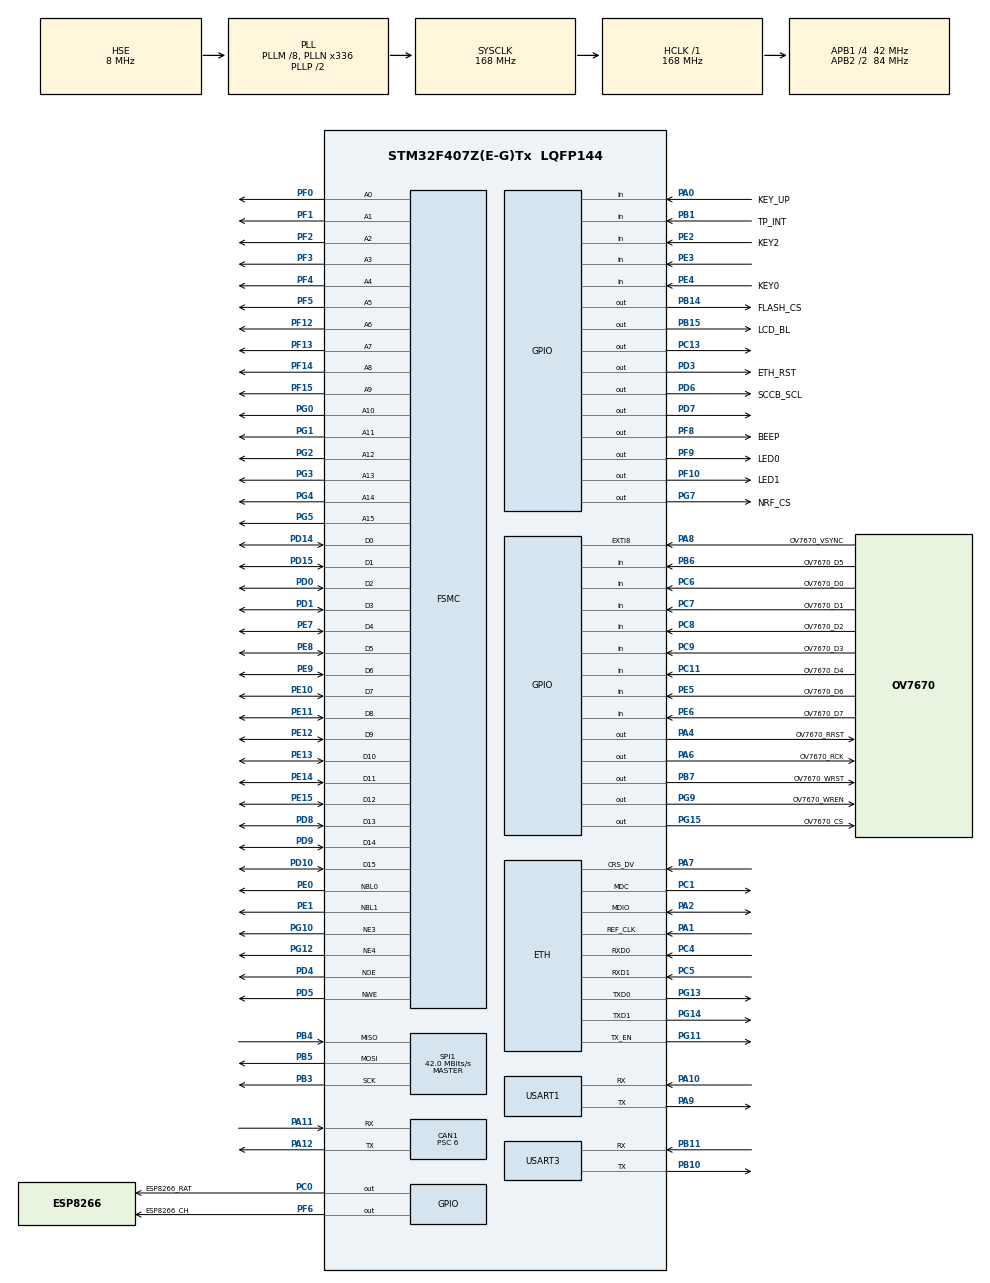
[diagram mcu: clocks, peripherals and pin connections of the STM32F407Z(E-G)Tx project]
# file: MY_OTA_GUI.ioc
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CAN1.BS1=CAN_BS1_11TQ
CAN1.BS2=CAN_BS2_2TQ
CAN1.CalculateBaudRate=500000
CAN1.CalculateTimeBit=2000
CAN1.CalculateTimeQuantum=142.85714285714286
CAN1.Prescaler=6
ETH.MediaInterface=HAL_ETH_RMII_MODE
FREERTOS.Tasks01=defaultTask,24,128,StartDefaultTask,Default,NULL,Dynamic,NULL,NULL
FREERTOS.configENABLE_FPU=1
FREERTOS.configTOTAL_HEAP_SIZE=65536
FSMC.AddressSetupTime3=0
FSMC.AddressSetupTime4=0
FSMC.BusTurnAroundDuration3=0
FSMC.BusTurnAroundDuration4=5
FSMC.DataSetupTime3=24
FSMC.DataSetupTime4=30
FSMC.WriteOperation3=FSMC_WRITE_OPERATION_ENABLE
FSMC.WriteOperation4=FSMC_WRITE_OPERATION_ENABLE
Mcu.Family=STM32F4
Mcu.Name=STM32F407Z(E-G)Tx
Mcu.Package=LQFP144
NVIC.EXTI9_5_IRQn=true\:5\:0\:false\:false\:true\:true\:true\:true\:true
NVIC.PriorityGroup=NVIC_PRIORITYGROUP_4
NVIC.TIM3_IRQn=true\:15\:0\:false\:false\:true\:false\:false\:true\:true
NVIC.TimeBase=TIM3_IRQn
NVIC.TimeBaseIP=TIM3
NVIC.USART1_IRQn=true\:5\:0\:false\:false\:true\:true\:true\:true\:true
PA0-WKUP.GPIO_Label=KEY_UP
PA0-WKUP.GPIO_PuPd=GPIO_PULLDOWN
PA0-WKUP.Signal=GPIO_Input
PA1.Mode=RMII
PA1.Signal=ETH_REF_CLK
PA10.Mode=Asynchronous
PA10.Signal=USART1_RX
PA11.Mode=CAN_Activate
PA11.Signal=CAN1_RX
PA12.Mode=CAN_Activate
PA12.Signal=CAN1_TX
PA13.Mode=Serial_Wire
PA13.Signal=SYS_JTMS-SWDIO
PA14.Mode=Serial_Wire
PA14.Signal=SYS_JTCK-SWCLK
PA2.Mode=RMII
PA2.Signal=ETH_MDIO
PA4.GPIO_Label=OV7670_RRST
PA4.Signal=GPIO_Output
PA6.GPIO_Label=OV7670_RCK
PA6.Signal=GPIO_Output
PA7.Mode=RMII
PA7.Signal=ETH_CRS_DV
PA8.GPIO_Label=OV7670_VSYNC
PA8.GPIO_ModeDefaultEXTI=GPIO_MODE_IT_FALLING
PA8.Signal=GPXTI8
PA9.Mode=Asynchronous
PA9.Signal=USART1_TX
PB1.GPIO_Label=TP_INT
PB1.GPIO_PuPd=GPIO_PULLUP
PB1.Signal=GPIO_Input
PB10.Mode=Asynchronous
PB10.Signal=USART3_TX
PB11.Mode=Asynchronous
PB11.Signal=USART3_RX
PB14.GPIO_Label=FLASH_CS
PB14.GPIO_PuPd=GPIO_PULLUP
PB14.PinState=GPIO_PIN_SET
PB14.Signal=GPIO_Output
PB15.GPIO_Label=LCD_BL
PB15.GPIO_PuPd=GPIO_PULLDOWN
PB15.Signal=GPIO_Output
PB3.GPIO_Speed=GPIO_SPEED_FREQ_MEDIUM
PB3.Mode=Full_Duplex_Master
PB3.Signal=SPI1_SCK
PB4.GPIO_Speed=GPIO_SPEED_FREQ_MEDIUM
PB4.Mode=Full_Duplex_Master
PB4.Signal=SPI1_MISO
PB5.GPIO_Speed=GPIO_SPEED_FREQ_MEDIUM
PB5.Mode=Full_Duplex_Master
PB5.Signal=SPI1_MOSI
PB6.GPIO_Label=OV7670_D5
PB6.GPIO_PuPd=GPIO_PULLDOWN
PB6.Signal=GPIO_Input
PB7.GPIO_Label=OV7670_WRST
PB7.Signal=GPIO_Output
PC0.GPIO_Label=ESP8266_RAT
PC0.PinState=GPIO_PIN_SET
PC0.Signal=GPIO_Output
PC1.Mode=RMII
PC1.Signal=ETH_MDC
PC11.GPIO_Label=OV7670_D4
PC11.GPIO_PuPd=GPIO_PULLDOWN
PC11.Signal=GPIO_Input
PC13-ANTI_TAMP.Signal=GPIO_Output
PC4.Mode=RMII
PC4.Signal=ETH_RXD0
PC5.Mode=RMII
PC5.Signal=ETH_RXD1
PC6.GPIO_Label=OV7670_D0
PC6.GPIO_PuPd=GPIO_PULLDOWN
PC6.Signal=GPIO_Input
PC7.GPIO_Label=OV7670_D1
PC7.GPIO_PuPd=GPIO_PULLDOWN
PC7.Signal=GPIO_Input
PC8.GPIO_Label=OV7670_D2
PC8.GPIO_PuPd=GPIO_PULLDOWN
PC8.Signal=GPIO_Input
PC9.GPIO_Label=OV7670_D3
PC9.GPIO_PuPd=GPIO_PULLDOWN
PC9.Signal=GPIO_Input
PD0.GPIO_Speed_High_Default=GPIO_SPEED_FREQ_MEDIUM
PD0.Signal=FSMC_D2_DA2
PD1.GPIO_Speed_High_Default=GPIO_SPEED_FREQ_MEDIUM
PD1.Signal=FSMC_D3_DA3
PD10.GPIO_Speed_High_Default=GPIO_SPEED_FREQ_MEDIUM
PD10.Signal=FSMC_D15_DA15
PD14.GPIO_Speed_High_Default=GPIO_SPEED_FREQ_MEDIUM
PD14.Signal=FSMC_D0_DA0
PD15.GPIO_Speed_High_Default=GPIO_SPEED_FREQ_MEDIUM
PD15.Signal=FSMC_D1_DA1
PD3.GPIO_Label=ETH_RST
PD3.GPIO_PuPd=GPIO_PULLUP
PD3.PinState=GPIO_PIN_SET
PD3.Signal=GPIO_Output
PD4.GPIO_Speed_High_Default=GPIO_SPEED_FREQ_MEDIUM
PD4.Signal=FSMC_NOE
PD5.GPIO_Speed_High_Default=GPIO_SPEED_FREQ_MEDIUM
PD5.Signal=FSMC_NWE
PD6.GPIO_Label=SCCB_SCL
PD6.GPIO_ModeDefaultOutputPP=GPIO_MODE_OUTPUT_OD
PD6.GPIO_PuPd=GPIO_PULLUP
PD6.PinState=GPIO_PIN_SET
PD6.Signal=GPIO_Output
PD7.GPIO_ModeDefaultOutputPP=GPIO_MODE_OUTPUT_OD
PD7.GPIO_PuPd=GPIO_PULLUP
PD7.Signal=GPIO_Output
PD8.GPIO_Speed_High_Default=GPIO_SPEED_FREQ_MEDIUM
PD8.Signal=FSMC_D13_DA13
PD9.GPIO_Speed_High_Default=GPIO_SPEED_FREQ_MEDIUM
PD9.Signal=FSMC_D14_DA14
PE0.GPIO_Speed_High_Default=GPIO_SPEED_FREQ_MEDIUM
PE0.Signal=FSMC_NBL0
PE1.GPIO_Speed_High_Default=GPIO_SPEED_FREQ_MEDIUM
PE1.Signal=FSMC_NBL1
PE10.GPIO_Speed_High_Default=GPIO_SPEED_FREQ_MEDIUM
PE10.Signal=FSMC_D7_DA7
PE11.GPIO_Speed_High_Default=GPIO_SPEED_FREQ_MEDIUM
PE11.Signal=FSMC_D8_DA8
PE12.GPIO_Speed_High_Default=GPIO_SPEED_FREQ_MEDIUM
PE12.Signal=FSMC_D9_DA9
PE13.GPIO_Speed_High_Default=GPIO_SPEED_FREQ_MEDIUM
PE13.Signal=FSMC_D10_DA10
PE14.GPIO_Speed_High_Default=GPIO_SPEED_FREQ_MEDIUM
PE14.Signal=FSMC_D11_DA11
PE15.GPIO_Speed_High_Default=GPIO_SPEED_FREQ_MEDIUM
PE15.Signal=FSMC_D12_DA12
PE2.GPIO_Label=KEY2
PE2.GPIO_PuPd=GPIO_PULLUP
PE2.Signal=GPIO_Input
PE3.Signal=GPIO_Input
PE4.GPIO_Label=KEY0
PE4.GPIO_PuPd=GPIO_PULLUP
PE4.Signal=GPIO_Input
PE5.GPIO_Label=OV7670_D6
PE5.GPIO_PuPd=GPIO_PULLDOWN
PE5.Signal=GPIO_Input
PE6.GPIO_Label=OV7670_D7
PE6.GPIO_PuPd=GPIO_PULLDOWN
PE6.Signal=GPIO_Input
PE7.GPIO_Speed_High_Default=GPIO_SPEED_FREQ_MEDIUM
PE7.Signal=FSMC_D4_DA4
PE8.GPIO_Speed_High_Default=GPIO_SPEED_FREQ_MEDIUM
PE8.Signal=FSMC_D5_DA5
PE9.GPIO_Speed_High_Default=GPIO_SPEED_FREQ_MEDIUM
PE9.Signal=FSMC_D6_DA6
PF0.GPIO_Speed_High_Default=GPIO_SPEED_FREQ_MEDIUM
PF0.Signal=FSMC_A0
PF1.GPIO_Speed_High_Default=GPIO_SPEED_FREQ_MEDIUM
PF1.Signal=FSMC_A1
PF10.GPIO_Label=LED1
PF10.GPIO_PuPd=GPIO_PULLUP
PF10.PinState=GPIO_PIN_SET
PF10.Signal=GPIO_Output
PF12.GPIO_Speed_High_Default=GPIO_SPEED_FREQ_MEDIUM
PF12.Signal=FSMC_A6
PF13.GPIO_Speed_High_Default=GPIO_SPEED_FREQ_MEDIUM
PF13.Signal=FSMC_A7
PF14.GPIO_Speed_High_Default=GPIO_SPEED_FREQ_MEDIUM
PF14.Signal=FSMC_A8
PF15.GPIO_Speed_High_Default=GPIO_SPEED_FREQ_MEDIUM
PF15.Signal=FSMC_A9
PF2.GPIO_Speed_High_Default=GPIO_SPEED_FREQ_MEDIUM
PF2.Signal=FSMC_A2
PF3.GPIO_Speed_High_Default=GPIO_SPEED_FREQ_MEDIUM
PF3.Signal=FSMC_A3
PF4.GPIO_Speed_High_Default=GPIO_SPEED_FREQ_MEDIUM
PF4.Signal=FSMC_A4
PF5.GPIO_Speed_High_Default=GPIO_SPEED_FREQ_MEDIUM
PF5.Signal=FSMC_A5
PF6.GPIO_Label=ESP8266_CH
PF6.PinState=GPIO_PIN_SET
PF6.Signal=GPIO_Output
PF8.GPIO_Label=BEEP
PF8.GPIO_PuPd=GPIO_PULLDOWN
PF8.PinState=GPIO_PIN_RESET
PF8.Signal=GPIO_Output
PF9.GPIO_Label=LED0
PF9.GPIO_PuPd=GPIO_PULLUP
PF9.PinState=GPIO_PIN_SET
PF9.Signal=GPIO_Output
PG0.GPIO_Speed_High_Default=GPIO_SPEED_FREQ_MEDIUM
PG0.Signal=FSMC_A10
PG1.GPIO_Speed_High_Default=GPIO_SPEED_FREQ_MEDIUM
PG1.Signal=FSMC_A11
PG10.GPIO_Speed_High_Default=GPIO_SPEED_FREQ_MEDIUM
PG10.Mode=NorPsramChipSelect3_3
PG10.Signal=FSMC_NE3
PG11.Mode=RMII
PG11.Signal=ETH_TX_EN
PG12.GPIO_Speed_High_Default=GPIO_SPEED_FREQ_MEDIUM
PG12.Mode=NorPsramChipSelect4_4
PG12.Signal=FSMC_NE4
PG13.Mode=RMII
PG13.Signal=ETH_TXD0
PG14.Mode=RMII
PG14.Signal=ETH_TXD1
PG15.GPIO_Label=OV7670_CS
PG15.PinState=GPIO_PIN_SET
PG15.Signal=GPIO_Output
PG2.GPIO_Speed_High_Default=GPIO_SPEED_FREQ_MEDIUM
PG2.Signal=FSMC_A12
PG3.GPIO_Speed_High_Default=GPIO_SPEED_FREQ_MEDIUM
PG3.Signal=FSMC_A13
PG4.GPIO_Speed_High_Default=GPIO_SPEED_FREQ_MEDIUM
PG4.Signal=FSMC_A14
PG5.GPIO_Speed_High_Default=GPIO_SPEED_FREQ_MEDIUM
PG5.Signal=FSMC_A15
PG7.GPIO_Label=NRF_CS
PG7.GPIO_PuPd=GPIO_PULLUP
PG7.PinState=GPIO_PIN_SET
PG7.Signal=GPIO_Output
PG9.GPIO_Label=OV7670_WREN
PG9.Signal=GPIO_Output
PH0-OSC_IN.Mode=HSE-External-Oscillator
PH0-OSC_IN.Signal=RCC_OSC_IN
PH1-OSC_OUT.Mode=HSE-External-Oscillator
PH1-OSC_OUT.Signal=RCC_OSC_OUT
ProjectManager.HeapSize=0x800
ProjectManager.StackSize=0x1000
ProjectManager.TargetToolchain=CMake
RCC.48MHZClocksFreq_Value=84000000
RCC.AHBFreq_Value=168000000
RCC.APB1CLKDivider=RCC_HCLK_DIV4
RCC.APB1Freq_Value=42000000
RCC.APB1TimFreq_Value=84000000
RCC.APB2CLKDivider=RCC_HCLK_DIV2
RCC.APB2Freq_Value=84000000
RCC.APB2TimFreq_Value=168000000
RCC.CortexFreq_Value=168000000
RCC.HCLKFreq_Value=168000000
RCC.HSE_VALUE=8000000
RCC.HSI_VALUE=16000000
RCC.LSE_VALUE=32768
RCC.PLLM=8
RCC.PLLN=336
RCC.PLLSourceVirtual=RCC_PLLSOURCE_HSE
RCC.SYSCLKFreq_VALUE=168000000
RCC.SYSCLKSource=RCC_SYSCLKSOURCE_PLLCLK
RCC.VCOOutputFreq_Value=336000000
SH.FSMC_A0.0=FSMC_A0,16b-a4
SH.FSMC_A0.1=FSMC_A0,16b-a3
SH.FSMC_A1.0=FSMC_A1,16b-a4
SH.FSMC_A1.1=FSMC_A1,16b-a3
SH.FSMC_A10.0=FSMC_A10,16b-a4
SH.FSMC_A10.1=FSMC_A10,16b-a3
SH.FSMC_A11.0=FSMC_A11,16b-a4
SH.FSMC_A11.1=FSMC_A11,16b-a3
SH.FSMC_A12.0=FSMC_A12,16b-a4
SH.FSMC_A12.1=FSMC_A12,16b-a3
SH.FSMC_A13.0=FSMC_A13,16b-a4
SH.FSMC_A13.1=FSMC_A13,16b-a3
SH.FSMC_A14.0=FSMC_A14,16b-a4
SH.FSMC_A14.1=FSMC_A14,16b-a3
SH.FSMC_A15.0=FSMC_A15,16b-a4
SH.FSMC_A15.1=FSMC_A15,16b-a3
SH.FSMC_A2.0=FSMC_A2,16b-a4
SH.FSMC_A2.1=FSMC_A2,16b-a3
SH.FSMC_A3.0=FSMC_A3,16b-a4
SH.FSMC_A3.1=FSMC_A3,16b-a3
SH.FSMC_A4.0=FSMC_A4,16b-a4
SH.FSMC_A4.1=FSMC_A4,16b-a3
SH.FSMC_A5.0=FSMC_A5,16b-a4
SH.FSMC_A5.1=FSMC_A5,16b-a3
SH.FSMC_A6.0=FSMC_A6,16b-a4
SH.FSMC_A6.1=FSMC_A6,16b-a3
SH.FSMC_A7.0=FSMC_A7,16b-a4
SH.FSMC_A7.1=FSMC_A7,16b-a3
SH.FSMC_A8.0=FSMC_A8,16b-a4
SH.FSMC_A8.1=FSMC_A8,16b-a3
SH.FSMC_A9.0=FSMC_A9,16b-a4
SH.FSMC_A9.1=FSMC_A9,16b-a3
SH.FSMC_D0_DA0.0=FSMC_D0,16b-d4
SH.FSMC_D0_DA0.1=FSMC_D0,16b-d3
SH.FSMC_D10_DA10.0=FSMC_D10,16b-d4
SH.FSMC_D10_DA10.1=FSMC_D10,16b-d3
SH.FSMC_D11_DA11.0=FSMC_D11,16b-d4
SH.FSMC_D11_DA11.1=FSMC_D11,16b-d3
SH.FSMC_D12_DA12.0=FSMC_D12,16b-d4
SH.FSMC_D12_DA12.1=FSMC_D12,16b-d3
SH.FSMC_D13_DA13.0=FSMC_D13,16b-d4
SH.FSMC_D13_DA13.1=FSMC_D13,16b-d3
SH.FSMC_D14_DA14.0=FSMC_D14,16b-d4
SH.FSMC_D14_DA14.1=FSMC_D14,16b-d3
SH.FSMC_D15_DA15.0=FSMC_D15,16b-d4
SH.FSMC_D15_DA15.1=FSMC_D15,16b-d3
SH.FSMC_D1_DA1.0=FSMC_D1,16b-d4
SH.FSMC_D1_DA1.1=FSMC_D1,16b-d3
SH.FSMC_D2_DA2.0=FSMC_D2,16b-d4
SH.FSMC_D2_DA2.1=FSMC_D2,16b-d3
SH.FSMC_D3_DA3.0=FSMC_D3,16b-d4
SH.FSMC_D3_DA3.1=FSMC_D3,16b-d3
SH.FSMC_D4_DA4.0=FSMC_D4,16b-d4
SH.FSMC_D4_DA4.1=FSMC_D4,16b-d3
SH.FSMC_D5_DA5.0=FSMC_D5,16b-d4
SH.FSMC_D5_DA5.1=FSMC_D5,16b-d3
SH.FSMC_D6_DA6.0=FSMC_D6,16b-d4
SH.FSMC_D6_DA6.1=FSMC_D6,16b-d3
SH.FSMC_D7_DA7.0=FSMC_D7,16b-d4
SH.FSMC_D7_DA7.1=FSMC_D7,16b-d3
SH.FSMC_D8_DA8.0=FSMC_D8,16b-d4
SH.FSMC_D8_DA8.1=FSMC_D8,16b-d3
SH.FSMC_D9_DA9.0=FSMC_D9,16b-d4
SH.FSMC_D9_DA9.1=FSMC_D9,16b-d3
SH.FSMC_NBL0.0=FSMC_NBL0,2ByteEnable3
SH.FSMC_NBL1.0=FSMC_NBL1,2ByteEnable3
SH.FSMC_NOE.0=FSMC_NOE,Sram4
SH.FSMC_NOE.1=FSMC_NOE,Sram3
SH.FSMC_NWE.0=FSMC_NWE,Sram4
SH.FSMC_NWE.1=FSMC_NWE,Sram3
SPI1.CLKPhase=SPI_PHASE_2EDGE
SPI1.CLKPolarity=SPI_POLARITY_HIGH
SPI1.CalculateBaudRate=42.0 MBits/s
SPI1.Direction=SPI_DIRECTION_2LINES
SPI1.Mode=SPI_MODE_MASTER
SPI1.VirtualType=VM_MASTER
USART1.VirtualMode=VM_ASYNC
USART3.VirtualMode=VM_ASYNC
VP_FREERTOS_VS_CMSIS_V2.Mode=CMSIS_V2
VP_SYS_VS_tim3.Mode=TIM3
board=custom

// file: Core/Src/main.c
/* USER CODE BEGIN Header */
/**
  ******************************************************************************
  * @file           : main.c
  * @brief          : Main program body
  ******************************************************************************
  * @attention
  *
  * Copyright (c) 2026 STMicroelectronics.
  * All rights reserved.
  *
  * This software is licensed under terms that can be found in the LICENSE file
  * in the root directory of this software component.
  * If no LICENSE file comes with this software, it is provided AS-IS.
  *
  ******************************************************************************
  */
/* USER CODE END Header */
#include "main.h"
#include "cmsis_os.h"
#include "can.h"
#include "eth.h"
#include "spi.h"
#include "usart.h"
#include "gpio.h"
#include "fsmc.h"

/* USER CODE BEGIN Includes */
#include <stdio.h>
#include "nt35510.h"
#include "sim_mode.h"
/* USER CODE END Includes */

/* USER CODE BEGIN PD */

/* ---- 批烧模式: 如果有 batch.h 则只写 SPI Flash, 不启 GUI ---- */
#ifdef BATCH_FLASH
#include "batch.h"
#endif

/* USER CODE END PD */

/* USER CODE BEGIN PV */
volatile uint8_t  g_rx_byte = 0;   /* 接收缓冲 — ISR 写入, Task 消费      */
volatile uint8_t  g_rx_flag = 0;   /* 接收完成标志: 1=有新数据           */
/* USER CODE END PV */

void SystemClock_Config(void);
void MX_FREERTOS_Init(void);
/* USER CODE BEGIN PFP */
static void PrintSystemInfo(void);
/* USER CODE END PFP */

int main(void)
{

  /* USER CODE BEGIN 1 */
  /* VTOR: STM32_Drivers 编译 system_stm32f4xx.c 时不带 USER_VECT_TAB_ADDRESS */
  SCB->VTOR = (uint32_t)0x08010000;

#ifdef SIMULATION
  SIM_Init();
#endif
  /* USER CODE END 1 */

  /* MCU Configuration--------------------------------------------------------*/

  /* Reset of all peripherals, Initializes the Flash interface and the Systick. */
  HAL_Init();

  /* Configure the system clock */
  SystemClock_Config();

  /* USER CODE BEGIN SysInit */
  /* Bootloader 跳转前关断了全局中断 (PRIMASK=1)，APP 必须恢复 */
  __set_PRIMASK(0);
  /* USER CODE END SysInit */

  /* Initialize all configured peripherals */
  MX_GPIO_Init();
  MX_USART1_UART_Init();
#if 0
  MX_ETH_Init();  /* ETH PHY 未连接时卡死 */
#endif
  MX_FSMC_Init();
  MX_SPI1_Init();
  MX_CAN1_Init();
  MX_USART3_UART_Init();
  /* USER CODE BEGIN 2 */

  /* ---- 按键重配: FSMC 覆盖了 PE2-PE4, 重新设为输入 ---- */
  GPIO_InitTypeDef key_fix = {0};
  key_fix.Pin = KEY1_Pin | KEY2_Pin | KEY0_Pin;
  key_fix.Mode = GPIO_MODE_INPUT;
  key_fix.Pull = GPIO_PULLUP;
  HAL_GPIO_Init(GPIOE, &key_fix);

  /* LED0 心跳 — PF9 低电平点亮 */
  HAL_GPIO_WritePin(LED0_GPIO_Port, LED0_Pin, GPIO_PIN_RESET);

  /* ---- LCD 背光 + 初始化 ---- */
  HAL_GPIO_WritePin(LCD_BL_GPIO_Port, LCD_BL_Pin, GPIO_PIN_SET);
  NT35510_Init();

  /* ---- 系统信息 ---- */
  PrintSystemInfo();

  /* ---- 启动 UART 中断接收 (FreeRTOS 回显) ---- */
  HAL_UART_Receive_IT(&huart1, (uint8_t *)&g_rx_byte, 1);
  /* USER CODE END 2 */

  /* Init scheduler */
  osKernelInitialize();  /* Call init function for freertos objects (in cmsis_os2.c) */
  MX_FREERTOS_Init();

  /* Start scheduler */
  osKernelStart();

  /* We should never get here as control is now taken by the scheduler */

  /* Infinite loop */
  while (1)
  {

    /* USER CODE BEGIN 3 */
    /* FreeRTOS 已接管 — LED 心跳 + UART 回显由 defaultTask 处理 */
    /* 此循环永不执行，仅作安全兜底                                    */
  /* USER CODE END 3 */
  }
}

void SystemClock_Config(void)
{
  RCC_OscInitTypeDef RCC_OscInitStruct = {0};
  RCC_ClkInitTypeDef RCC_ClkInitStruct = {0};

  /** Configure the main internal regulator output voltage
  */
  __HAL_RCC_PWR_CLK_ENABLE();
  __HAL_PWR_VOLTAGESCALING_CONFIG(PWR_REGULATOR_VOLTAGE_SCALE1);

  /** Initializes the RCC Oscillators according to the specified parameters
  * in the RCC_OscInitTypeDef structure.
  */
  RCC_OscInitStruct.OscillatorType = RCC_OSCILLATORTYPE_HSE;
  RCC_OscInitStruct.HSEState = RCC_HSE_ON;
  RCC_OscInitStruct.PLL.PLLState = RCC_PLL_ON;
  RCC_OscInitStruct.PLL.PLLSource = RCC_PLLSOURCE_HSE;
  RCC_OscInitStruct.PLL.PLLM = 8;
  RCC_OscInitStruct.PLL.PLLN = 336;
  RCC_OscInitStruct.PLL.PLLP = RCC_PLLP_DIV2;
  RCC_OscInitStruct.PLL.PLLQ = 4;
  if (HAL_RCC_OscConfig(&RCC_OscInitStruct) != HAL_OK)
  {
    Error_Handler();
  }

  /** Initializes the CPU, AHB and APB buses clocks
  */
  RCC_ClkInitStruct.ClockType = RCC_CLOCKTYPE_HCLK|RCC_CLOCKTYPE_SYSCLK
                              |RCC_CLOCKTYPE_PCLK1|RCC_CLOCKTYPE_PCLK2;
  RCC_ClkInitStruct.SYSCLKSource = RCC_SYSCLKSOURCE_PLLCLK;
  RCC_ClkInitStruct.AHBCLKDivider = RCC_SYSCLK_DIV1;
  RCC_ClkInitStruct.APB1CLKDivider = RCC_HCLK_DIV4;
  RCC_ClkInitStruct.APB2CLKDivider = RCC_HCLK_DIV2;

  if (HAL_RCC_ClockConfig(&RCC_ClkInitStruct, FLASH_LATENCY_5) != HAL_OK)
  {
    Error_Handler();
  }
}

/* USER CODE BEGIN 4 */

/* ---- 启动信息打印 ---- */
static void PrintSystemInfo(void)
{
    uint32_t sysclk = HAL_RCC_GetSysClockFreq();
    uint32_t hclk   = HAL_RCC_GetHCLKFreq();
    uint32_t pclk1  = HAL_RCC_GetPCLK1Freq();
    uint32_t pclk2  = HAL_RCC_GetPCLK2Freq();

    printf("\r\n============================================\r\n");
    printf("  MY_OTA_GUI -- Start\r\n");
    printf("============================================\r\n");
    printf("  MCU     : STM32F407ZGT6 @ 168MHz\r\n");
    printf("  SYSCLK  : %lu MHz\r\n", sysclk / 1000000);
    printf("  HCLK    : %lu MHz\r\n", hclk   / 1000000);
    printf("  APB1    : %lu MHz\r\n", pclk1  / 1000000);
    printf("  APB2    : %lu MHz\r\n", pclk2  / 1000000);
    printf("  USART1  : 115200-8N1\r\n");
    printf("============================================\r\n");
}

/* USER CODE END 4 */

void HAL_TIM_PeriodElapsedCallback(TIM_HandleTypeDef *htim)
{
  if (htim->Instance == TIM3)
  {
    HAL_IncTick();
  }
}

void Error_Handler(void)
{
  __disable_irq();
  while (1)
  {
  }
}

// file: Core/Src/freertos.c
/* USER CODE BEGIN Header */
/**
  ******************************************************************************
  * File Name          : freertos.c
  * Description        : Code for freertos applications
  ******************************************************************************
  */
/* USER CODE END Header */

#include "FreeRTOS.h"
#include "task.h"
#include "main.h"
#include "cmsis_os.h"

/* USER CODE BEGIN Includes */
#include "usart.h"
#include <stdio.h>
#include <string.h>
#include "lvgl.h"
#include "lv_port_disp.h"
#include "lv_fs_spi_flash.h"
#include "en25q128.h"
#include "touch/touch.h"
#include "canif.h"
#include "inter_flash_cfg.h"
#include "app_ui.h"
#include "mode_ui.h"
#include "settings_ui.h"
#include "clock_ui.h"
#include "camera_ui.h"
#include "ov7670.h"
#include "spi_img_loader.h"
#include "lfs_port.h"
#include "wifi_function.h"          /* ESP8266 WiFi 模块 AT 驱动 */
/* hw_diag.h — 探索期遗留，擦写 SPI Flash 影响启动时间，移除 */
/* #include "hw_diag.h" */

/* ── 自定义中文字体（OTA 进度提示用）── */
LV_FONT_DECLARE(ui_font_chinese_16);
/* USER CODE END Includes */

/* USER CODE BEGIN PFP */
/* 备份进度回调：仅刷屏不跑定时器（防 sysmon_timer 访问已销毁控件） */
static void backup_progress_cb(uint32_t cur, uint32_t tot, const char *phase)
{
    char buf[56];
    snprintf(buf, sizeof(buf), "OTA 备份中\n\n%s\n%lu / %lu", phase, (unsigned long)cur, (unsigned long)tot);
    lv_obj_t *child = lv_obj_get_child(lv_scr_act(), -1);
    if (child) lv_label_set_text(child, buf);
    lv_refr_now(NULL);  /* 只刷屏，不跑定时器 */
}
/* USER CODE END PFP */

/* USER CODE BEGIN Variables */
extern volatile uint8_t  g_rx_byte;
extern volatile uint8_t  g_rx_flag;

/* -- FreeRTOS 任务栈大小定义 (所有尺寸以字为单位) -- */
#define GUI_TASK_STACK_SIZE     (1024 * 24)  /* 24KB: LVGL + camera, 翻倍预留 (原 12KB, 高水位 ~9.5KB) */
#define TOUCH_TASK_STACK_SIZE   (1024 * 4)   /*  4KB: 触控 I2C 轮询, 重点扩充 (原 512B, 高水位 425B) */
#define CANRX_TASK_STACK_SIZE   (1024 * 4)   /*  4KB: CAN 接收 + printf, 翻倍 (原 2KB) */
#define WIFI_TASK_STACK_SIZE    (1024 * 4)   /*  4KB: ESP8266 AT + sprintf, 翻倍 (原 2KB) */
#define DEFAULT_TASK_STACK_SIZE (1024 * 4)   /*  4KB: LED + UART 回显, 重点扩充 (原 512B, 高水位 413B) */

osThreadId_t guiTaskHandle;
const osThreadAttr_t guiTask_attributes = {
  .name = "guiTask",
  .stack_size = GUI_TASK_STACK_SIZE,
  .priority = (osPriority_t) osPriorityAboveNormal,
};

osThreadId_t touchTaskHandle;
const osThreadAttr_t touchTask_attributes = {
  .name = "touchTask",
  .stack_size = TOUCH_TASK_STACK_SIZE,
  .priority = (osPriority_t) osPriorityAboveNormal,
};

osThreadId_t canRxTaskHandle;
const osThreadAttr_t canRxTask_attributes = {
  .name = "canRxTask",
  .stack_size = CANRX_TASK_STACK_SIZE,
  .priority = (osPriority_t) osPriorityNormal,
};

osThreadId_t wifiTaskHandle;
const osThreadAttr_t wifiTask_attributes = {
  .name = "wifiTask",
  .stack_size = WIFI_TASK_STACK_SIZE,
  .priority = (osPriority_t) osPriorityBelowNormal,  /* 低优先级, 不干扰主界面响应 */
};
/* ── CAN → LVGL 延迟更新标志 (CAN 任务只设标志, GUI 任务消费, 避免线程冲突) ── */
volatile uint8_t g_can_sensor_pending = 0;
volatile uint8_t g_can_time_pending   = 0;
volatile uint8_t g_can_time_buf[6]    = {0};
/* USER CODE END Variables */
/* Definitions for defaultTask */
osThreadId_t defaultTaskHandle;
const osThreadAttr_t defaultTask_attributes = {
  .name = "defaultTask",
  .stack_size = DEFAULT_TASK_STACK_SIZE,
  .priority = (osPriority_t) osPriorityNormal,
};

/* USER CODE BEGIN FunctionPrototypes */

/**
 * ============================================================
 *  GUI 主任务 (APPLICATION 层)
 * ============================================================
 * 职责: 管理整个图形界面生命周期
 *
 * 初始化顺序 (必须):
 *   1. LVGL 内核 + 显示驱动 (lcd_init / lv_port_disp_init)
 *   2. SPI Flash 驱动 (图片文件系统基石)
 *   3. LittleFS 挂载 (管理文件备份)
 *   4. CAN 接口启动 (接收 F103 传感器数据)
 *   5. 触摸屏初始化 + 注册 LVGL 输入设备
 *   6. 从 SPI Flash 预加载图片到外部 SRAM
 *   7. 创建四屏 UI 对象 (Home / Mode / Settings / Clock)
 *
 * 主循环逻辑:
 *   - 摄像头激活时: camera_refresh + lv_timer_handler
 *   - 正常模式: lv_timer_handler(处理触摸事件+渲染)
 *   - 每次循环检查 CAN 延迟更新标志
 *   - osDelay(5) 让出 CPU 给低优先级任务
 */

void StartGUITask(void *argument);
void StartTouchTask(void *argument);
void StartCanRxTask(void *argument);
void StartWiFiTask(void *argument);
/* USER CODE END FunctionPrototypes */

void StartDefaultTask(void *argument);

void MX_FREERTOS_Init(void); /* (MISRA C 2004 rule 8.1) */

void MX_FREERTOS_Init(void) {

  /* Create the thread(s) */
  /* creation of defaultTask */
  defaultTaskHandle = osThreadNew(StartDefaultTask, NULL, &defaultTask_attributes);

  /* USER CODE BEGIN RTOS_THREADS */
  guiTaskHandle  = osThreadNew(StartGUITask, NULL, &guiTask_attributes);
  touchTaskHandle = osThreadNew(StartTouchTask, NULL, &touchTask_attributes);
  canRxTaskHandle = osThreadNew(StartCanRxTask, NULL, &canRxTask_attributes);
  wifiTaskHandle  = osThreadNew(StartWiFiTask, NULL, &wifiTask_attributes);
  /* USER CODE END RTOS_THREADS */

}

void StartDefaultTask(void *argument)
{
  /* USER CODE BEGIN StartDefaultTask */
  uint32_t last_tick = osKernelGetTickCount();
  uint8_t  ota_seq = 0;    /* OTA 触发序列检测状态机 */

  for(;;) {
    osDelay(10);

    /* LED 心跳 */
    if (osKernelGetTickCount() - last_tick >= 500) {
        last_tick = osKernelGetTickCount();
        HAL_GPIO_TogglePin(LED0_GPIO_Port, LED0_Pin);
    }

    /* UART 回显 + OTA 触发检测 ("OTA" 或 "ota") */
    if (g_rx_flag) {
        g_rx_flag = 0;
        char c = (char)g_rx_byte;

        if (c == 'O' || c == 'o') ota_seq = 1;
        else if (ota_seq == 1 && (c == 'T' || c == 't')) ota_seq = 2;
        else if (ota_seq == 2 && (c == 'A' || c == 'a')) {
            ota_seq = 0;
            printf("\r\n[APP] OTA trigger via UART!\r\n");
            inter_flash_cfg_set_app_update_flag(1);
            HAL_Delay(100);
            NVIC_SystemReset();
        } else {
            ota_seq = 0;
        }

        HAL_UART_Transmit(&huart1, (uint8_t *)&g_rx_byte, 1, HAL_MAX_DELAY);
        HAL_UART_Receive_IT(&huart1, (uint8_t *)&g_rx_byte, 1);
    }
  }
  /* USER CODE END StartDefaultTask */
}

/* USER CODE BEGIN Application */

void StartGUITask(void *argument)
{
    printf("[GUI] Task start, free heap=%u\r\n", (unsigned)xPortGetFreeHeapSize());

    lv_init();
    lv_port_disp_init();
    printf("[GUI] LVGL+Display init done\r\n");

    /* ---- SPI Flash 驱动 + LVGL 文件系统 (图片按需从 Flash 读取) ---- */
    EN25Q128_Init();            /* SPI1 寄存器级重配 (Mode3, BR=SAFE)   */
    EN25Q128_SetSpeed(EN25Q128_BR_FAST);  /* 升速至 10.5MHz             */
    lv_fs_spi_flash_init();     /* 注册 "S:" 盘符 (只读)               */
    printf("[GUI] SPI Flash FS init done\r\n");

    /* ---- LittleFS 文件系统 (SPI Flash 0x000000~0xDFFFFF) ---- */
    lfs_storage_init();
    printf("[GUI] LittleFS init done\r\n");

    /* ---- CAN 接口启动 ---- */
    canif_init();

    /* 触摸屏初始化 + LVGL indev 注册 */
    touch_init();

    /* 从 SPI Flash 预加载图片到外部 SRAM */
    spi_img_load_all();

    /* 创建精简 GUI */
    app_ui_create();
    mode_ui_create();
    settings_ui_create();
    clock_ui_create();
    printf("[GUI] All UIs created (Home + Mode + Settings + Clock)\r\n");

    printf("[GUI] Init done, entering loop\r\n");

    for (;;) {
        /* ── 处理 CAN 数据延迟更新 (避免 CAN 任务直接调用 LVGL) ── */
        if (g_can_sensor_pending) {
            g_can_sensor_pending = 0;
            uint8_t key_id   = (g_can_sensor.key_event >> 4) & 0x0F;
            uint8_t key_type = g_can_sensor.key_event & 0x0F;
            app_ui_update_sensor(g_can_sensor.temperature,
                                 g_can_sensor.humidity,
                                 g_can_sensor.knob,
                                 key_id, key_type);
            app_ui_set_can_status(1);
        }
        if (g_can_time_pending) {
            g_can_time_pending = 0;
            app_ui_update_time(g_can_time_buf[0], g_can_time_buf[1],
                               g_can_time_buf[2], g_can_time_buf[3],
                               g_can_time_buf[4], g_can_time_buf[5]);
        }

        if (g_camera_active) {
            camera_refresh();
            lv_timer_handler();  /* 保持 LVGL 活性（Back 按钮响应、屏幕刷新） */
            osDelay(5);
            continue;
        }
        lv_timer_handler();

        /* OTA 触发：由按钮回调设标志，主循环执行（确保 LVGL 刷新完毕） */
        if (g_ota_pending) {
            g_ota_pending = 0;
            printf("[GUI] OTA pending: showing screen, then backup\n");

            /* 显示备份提示画面 */
            lv_obj_clean(lv_scr_act());
            lv_obj_set_style_bg_color(lv_scr_act(), lv_color_hex(0x000000), LV_PART_MAIN);
            lv_obj_t *lbl = lv_label_create(lv_scr_act());
            lv_label_set_text(lbl, "OTA 备份中\n\n正准备开始...");
            lv_obj_set_style_text_color(lbl, lv_color_hex(0xffffff), LV_PART_MAIN);
            lv_obj_set_style_text_font(lbl, &ui_font_chinese_16, LV_PART_MAIN);
            lv_obj_center(lbl);

            /* 多次调用 timer handler 确保 LCD 真正刷新 */
            for (int i = 0; i < 20; i++) {
                lv_timer_handler();
                osDelay(10);
            }

            /* 注册进度回调 → 备份期间实时刷新屏幕 */
            EN25Q128_SetBackupProgressCb(backup_progress_cb);
            /* LFS 文件备份（首选），失败降级到裸备份 */
            if (EN25Q128_BackupFirmwareLFS() != 0) {
                printf("[GUI] LFS backup failed, fallback to raw...\n");
                EN25Q128_BackupFirmware();
            }
            EN25Q128_SetBackupProgressCb(NULL);

            /* 更新提示 */
            lv_label_set_text(lbl, "OTA 备份完成!\n\n即将复位...");
            for (int i = 0; i < 10; i++) {
                lv_timer_handler();
                osDelay(10);
            }

            /* 设 OTA 标志并复位 */
            inter_flash_cfg_set_app_update_flag(1);
            osDelay(100);
            NVIC_SystemReset();
        }

        osDelay(5);
    }
}

/* ---- 独立触控轮询任务 (优先级高于 GUI, 不受渲染阻塞) ---- */
void StartTouchTask(void *argument)
{
    (void)argument;
    /* 等 GUI 任务完成触摸初始化 */
    osDelay(500);

    for (;;) {
        touch_poll();
        osDelay(10);  /* 100Hz 触控采样率 */
    }
}

/* ---- CAN 接收任务 (轮询 FIFO, 50Hz) ---- */
void StartCanRxTask(void *argument)
{
    (void)argument;
    uint8_t rx_buf[8];
    uint32_t rx_id;
    uint32_t diag_tick = 0;

    /* 等 GUI 任务完成初始化 */
    osDelay(1000);

    printf("[CAN] canRxTask started\r\n");

    for (;;) {
        uint8_t len = CAN1_Recv_Msg(&rx_id, rx_buf);
        if (len > 0) {
            /* 识别 F103 传感器帧 (ID=0x12) */
            if (rx_id == CAN_ID_SENSOR) {
                canif_parse_sensor(rx_buf, len);
                g_can_sensor_pending = 1;  /* GUI 任务统一更新 LVGL, 避免线程冲突 */
            }
            /* OTA 触发命令 (ID=0x0B3, Magic=BE AD BE EF) */
            else if (rx_id == CAN_ID_CALL_OTA && len >= 5) {
                if (rx_buf[0] == OTA_MAGIC_0 && rx_buf[1] == OTA_MAGIC_1 &&
                    rx_buf[2] == OTA_MAGIC_2 && rx_buf[3] == OTA_MAGIC_3 &&
                    rx_buf[4] == OTA_CMD_EXECUTE) {
                    printf("\r\n[CAN] OTA trigger via CAN!\r\n");
                    inter_flash_cfg_set_app_update_flag(1);
                    HAL_Delay(100);
                    NVIC_SystemReset();
                }
            }
            /* RTC 时间帧 (ID=0x13, F103 每秒发送) */
            else if (rx_id == CAN_ID_RTC_TIME && len >= 6) {
                for (int i = 0; i < 6; i++) g_can_time_buf[i] = rx_buf[i];
                g_can_time_pending = 1;
            }
            /* 未知 ID — 仅调试时打印 */
            else {
                printf("[CAN] Unknown ID=0x%03lx L=%u\r\n",
                       (unsigned long)rx_id, len);
            }
        }
        osDelay(20);  /* 50Hz 轮询 */
    }
}

/* ---- WiFi 任务 (ESP8266 初始化 + 连接维护) ---- */
#define WIFI_SSID       "Lee"          /* ← 修改为你的 WiFi 名称 */
#define WIFI_PASSWORD   ""      /* ← 修改为你的 WiFi 密码 */

void StartWiFiTask(void *argument)
{
    (void)argument;
    printf("[WiFi] Task started, waiting for system ready...\r\n");
    osDelay(3000);  /* 等 GUI/LVGL/SPI-Flash 全部就绪 */

    /* 使能 ESP8266 电源 (CH_PD = HIGH) */
    ESP8266_Choose(ENABLE);
    osDelay(500);

    /* 使能 USART3 RX 中断 — ESP8266 数据通过中断填充 wifi_config 缓冲区 */
    USART3->CR1 |= USART_CR1_RXNEIE;
    HAL_NVIC_SetPriority(USART3_IRQn, 5, 0);
    HAL_NVIC_EnableIRQ(USART3_IRQn);
    printf("[WiFi] USART3 RX interrupt enabled\r\n");

    /* 复位 ESP8266 并测试 AT */
    ESP8266_AT_Test();
    printf("[WiFi] AT OK -- module ready\r\n");

    /* 设置为 Station 模式 (连接外部路由器) */
    ESP8266_Net_Mode_Choose(STA);
    printf("[WiFi] Mode set to STA\r\n");

    /* 连接 WiFi 热点 */
    printf("[WiFi] Connecting to \"%s\"...\r\n", WIFI_SSID);
    if (ESP8266_JoinAP(WIFI_SSID, WIFI_PASSWORD)) {
        printf("[WiFi] Connected!\r\n");
        /* 查询并打印 IP */
        ESP8266_Cmd("AT+CIFSR", "OK", NULL, 1000);
        /* 启用多连接 */
        ESP8266_Enable_MultipleId(ENABLE);
        /* TCP Server (port 8080, for directed / sequential OTA) */
        if (ESP8266_StartOrShutServer(ENABLE, "8080", "0")) {
            printf("[WiFi] TCP server on port 8080 ready\r\n");
        }
    } else {
        printf("[WiFi] Failed to connect! Will retry...\r\n");
    }

    /* 主循环: 保持连接 + OTA 接收 */
    {
        uint32_t tick30 = 0;
        uint32_t ota_offset = 0;       /* 已接收字节数 */
        uint32_t ota_total  = 0;       /* 固件总大小 */
        uint8_t  ota_active = 0;       /* 正在 OTA 接收中 */
        uint8_t  ota_buf[256];         /* 临时写入缓冲区 */
        char     rx_line[1024];         /* 一行接收数据 */

        for (;;) {
            osDelay(10);
            tick30++;

            /* --- 非阻塞检查 ESP8266 接收帧 (不调用 ESP8266_ReceiveString, 它阻塞) --- */
            if (strEsp8266_Fram_Record.InfBit.FramFinishFlag) {
                strEsp8266_Fram_Record.InfBit.FramFinishFlag = 0;
                uint16_t flen = strEsp8266_Fram_Record.InfBit.FramLength;
                if (flen > sizeof(rx_line) - 1) flen = sizeof(rx_line) - 1;
                memcpy(rx_line, strEsp8266_Fram_Record.Data_RX_BUF, flen);
                rx_line[flen] = '\0';
                strEsp8266_Fram_Record.InfBit.FramLength = 0;

                /* +IPD frame: +IPD,<id>,<len>:<data> (MUX-mode with ID) */
                char *ipd = strstr(rx_line, "+IPD");
                if (ipd) {
                    /* extract data length (skip connection ID) */
                    uint32_t ipd_len = 0;
                    char *p = ipd + 5;
                    for (; *p && *p != ','; p++); /* skip ID */
                    if (*p == ',') {
                        p++;
                        for (; *p && *p != ':'; p++)
                            ipd_len = ipd_len * 10 + (uint32_t)(*p - '0');
                    }
                    /* point to data after colon */
                    char *p_data = strchr(ipd, ':');
                    if (p_data && ipd_len > 0 && ipd_len < 1024) {
                        p_data++;

                        /* WHO: reply with MCU UID (direct mode: AT+CIPSEND) */
                        if (strncmp(p_data, "WHO", 3) == 0) {
                            uint32_t uid0 = *(uint32_t*)0x1FFF7A10;
                            uint32_t uid1 = *(uint32_t*)0x1FFF7A14;
                            uint32_t uid2 = *(uint32_t*)0x1FFF7A18;
                            char rbuf[40];
                            int rn = snprintf(rbuf, sizeof(rbuf),
                                "ID:%08lX%08lX%08lX\r\n", uid0, uid1, uid2);
                            if (rn > 0) {
                                ESP8266_Usart("AT+CIPSEND=%d\r\n", rn);
                                osDelay(100);
                                ESP8266_Usart("%s", rbuf);
                            }
                            continue;
                        }

                        /* OTA:size (directed) or OTA:size:ip:port (broadcast) */
                        if (strncmp(p_data, "OTA:", 4) == 0 && !ota_active) {
                            char *sp = p_data + 4;
                            ota_total = 0;
                            for (; *sp && *sp != ':'; sp++)
                                ota_total = ota_total * 10 + (uint32_t)(*sp - '0');
                            if (ota_total > 4096 && ota_total <= 0x100000) {
                                char *srv_ip = 0, *srv_port = 0;
                                if (*sp == ':') {
                                    sp++; srv_ip = sp;
                                    for (; *sp && *sp != ':'; sp++);
                                    if (*sp == ':') { *sp = 0; srv_port = sp + 1; }
                                }
                                if (srv_ip && srv_port) {
                                    /* Broadcast: close UDP, connect TCP download */
                                    printf("[WiFi] OTA broadcast: %lu @ %s:%s\r\n",
                                           ota_total, srv_ip, srv_port);
                                    ESP8266_Usart("AT+CIPCLOSE\r\n"); osDelay(500);
                                    char cbuf[100];
                                    snprintf(cbuf, sizeof(cbuf),
                                        "AT+CIPSTART=\"TCP\",\"%s\",%s",srv_ip,srv_port);
                                    if (ESP8266_Cmd(cbuf, "OK", NULL, 3000)) {
                                        ota_active = 1; ota_offset = 8;
                                        for (uint32_t s = 0; s < 128; s++)
                                            EN25Q128_EraseSector(SPI_BAK_ADDR + s * 4096);
                                    }
                                } else {
                                    /* Directed: already TCP-connected */
                                    ota_active = 1; ota_offset = 8;
                                    for (uint32_t s = 0; s < 128; s++)
                                        EN25Q128_EraseSector(SPI_BAK_ADDR + s * 4096);
                                }
                            }
                            continue;
                        }
                        /* OTA data receive */
                        if (ota_active) {
                            uint32_t n = ipd_len;
                            if (n > 0 && n <= 256 && ota_offset - 8 + n <= ota_total) {
                                memcpy(ota_buf, p_data, n);
                                EN25Q128_Write(ota_buf, SPI_BAK_ADDR + ota_offset, n);
                                ota_offset += n;
                            }
                        }
                    }
                }
            }

            /* --- OTA 完成检查 --- */
            if (ota_active && ota_offset - 8 >= ota_total) {
                printf("[WiFi] OTA receive complete! (%lu bytes)\r\n", ota_total);
                uint8_t hdr[8];
                hdr[0] = (uint8_t)(SPI_BAK_MAGIC >> 0);
                hdr[1] = (uint8_t)(SPI_BAK_MAGIC >> 8);
                hdr[2] = (uint8_t)(SPI_BAK_MAGIC >> 16);
                hdr[3] = (uint8_t)(SPI_BAK_MAGIC >> 24);
                hdr[4] = (uint8_t)(ota_total >> 0);
                hdr[5] = (uint8_t)(ota_total >> 8);
                hdr[6] = (uint8_t)(ota_total >> 16);
                hdr[7] = (uint8_t)(ota_total >> 24);
                EN25Q128_Write(hdr, SPI_BAK_ADDR, 8);

                printf("[WiFi] Rebooting into bootloader for OTA...\r\n");
                osDelay(500);
                inter_flash_cfg_set_app_update_flag(1);
                osDelay(100);
                NVIC_SystemReset();
            }

            /* --- 每 30 秒保活检测 --- */
            if (tick30 >= 3000) {  /* 3000 × 10ms = 30s */
                tick30 = 0;
                if (!ESP8266_Cmd("AT", "OK", NULL, 200)) {
                    printf("[WiFi] Lost, reconnecting...\r\n");
                    ESP8266_Rst(); osDelay(1000);
                    ESP8266_AT_Test();
                    ESP8266_Net_Mode_Choose(STA);
                    ESP8266_JoinAP(WIFI_SSID, WIFI_PASSWORD);
                    ESP8266_Enable_MultipleId(ENABLE);
                    ESP8266_StartOrShutServer(ENABLE, "8080", "0");
                }
            }
        }
    }
}
/* USER CODE END Application */
